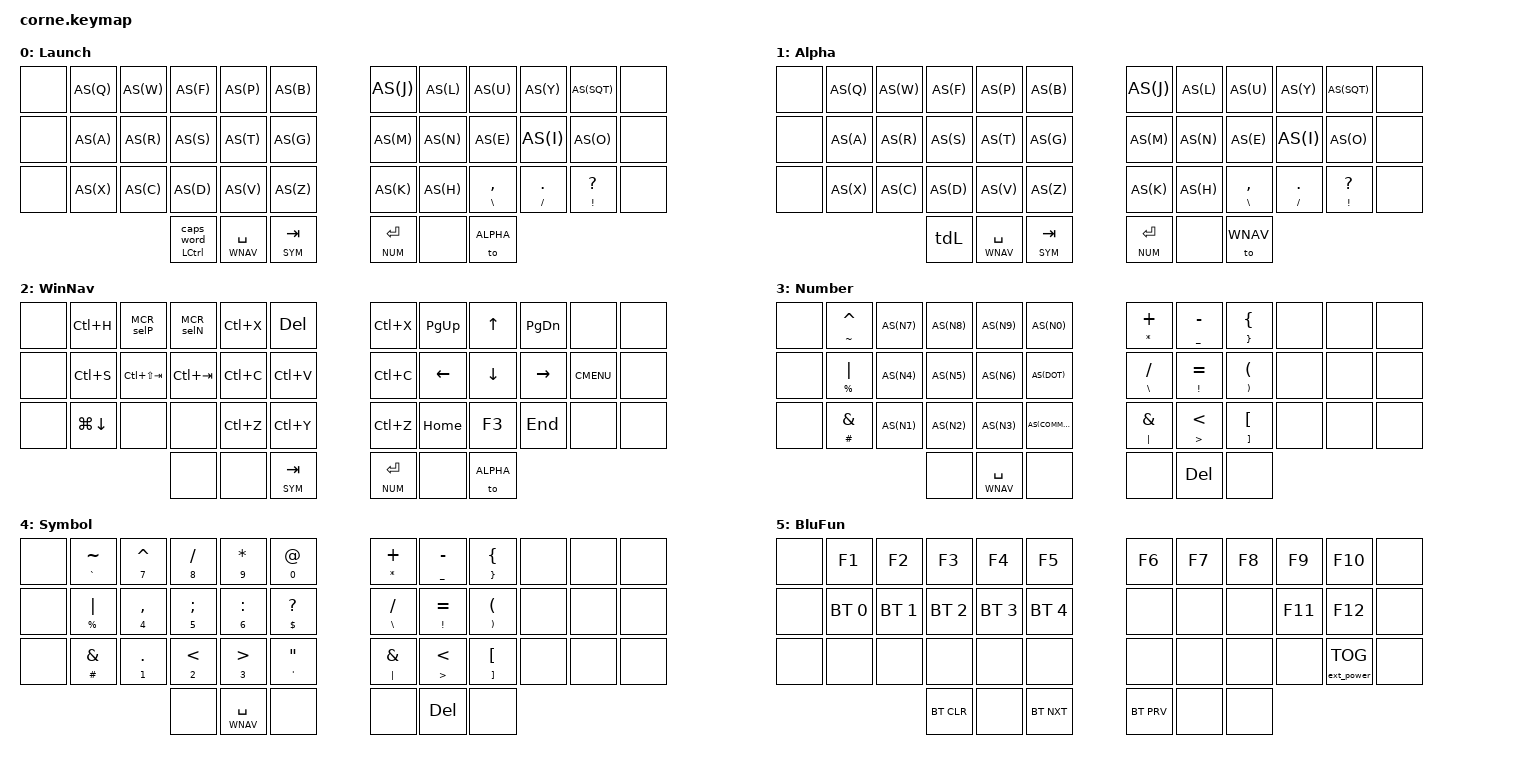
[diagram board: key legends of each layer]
/*
 * Copyright (c) 2020 The ZMK Contributors
 *
 * SPDX-License-Identifier: MIT
 */

#include <behaviors.dtsi>
#include <dt-bindings/zmk/keys.h>
#include <dt-bindings/zmk/bt.h>
#include <dt-bindings/zmk/ext_power.h>

#define XXX &none         // no physical keys
#define KNA &none         // key not applicable / unused

// Macros
#define AS(keycode) &as LS(keycode) keycode   // Autoshift
#define TS(keycode) &ts keycode keycode       // togglestick

// Windows Clipboard shortcuts
#define Win_RDO &kp LC(Y)
#define Win_PST &kp LC(V)
#define Win_CPY &kp LC(C)
#define Win_CUT &kp LC(X)
#define Win_UDO &kp LC(Z)
#define Win_REP &kp LC(H)
#define Win_SLA &kp LC(A)
#define Win_MIN &kp LG(DOWN)

// Layer definition
#define	LAUNCH  0
#define	ALPHA   1
#define	WNAV    2
#define	NUM     3
#define	SYM     4
#define	BLU     5
//#define VIM   6
//#define U_MEDIA  7
//#define U_NUM    8
//#define U_SYM    9
//#define U_FUN    10

/ {
    macros {
        MCR_selC: sel_word_cur {
            label = "macro_selectword_current";
            compatible = "zmk,behavior-macro";
            #binding-cells = <0>;
            bindings = <&macro_tap &kp LC(LEFT) &kp LC(LS(RIGHT))>;
        };
        MCR_selP: sel_word_prv {
            label = "macro_selectword_previous";
            compatible = "zmk,behavior-macro";
            #binding-cells = <0>;
            bindings = <&macro_tap &kp LC(LEFT) &kp LC(LEFT) &kp LC(LS(RIGHT))>;
        };
        MCR_selN: sel_word_nxt {
            label = "macro_selectword_next";
            compatible = "zmk,behavior-macro";
            #binding-cells = <0>;
            bindings = <&macro_tap &kp LC(RIGHT) &kp LC(LS(RIGHT))>;
        };
    };
};

/ {
    combos {
        compatible = "zmk,combos";
        combo_bspcL     { timeout-ms = <50>; key-positions = <15 16>; bindings = <&kp BSPC>;   };
        combo_bspcR     { timeout-ms = <50>; key-positions = <19 20>; bindings = <&kp BSPC>;   };
        combo_delL      { timeout-ms = <50>; key-positions = < 3  4>; bindings = <&kp DEL>;    };
        combo_delR      { timeout-ms = <50>; key-positions = < 7  8>; bindings = <&kp DEL>;    };
        combo_sysrstL   { timeout-ms = <50>; key-positions = < 1  5>; bindings = <&sys_reset>; };
        combo_sysrstR   { timeout-ms = <50>; key-positions = < 6 10>; bindings = <&sys_reset>; };
        combo_esc       { timeout-ms = <50>; key-positions = < 1  2>; bindings = <&kp ESC>;    };
        combo_blu_layer { timeout-ms = <50>; key-positions = < 1 25>; bindings = <&tog BLU>;   };
    };
};

/ {
     behaviors {
        as: auto_shift {
            compatible = "zmk,behavior-hold-tap";
            label = "AUTO_SHIFT";
            #binding-cells = <2>;
            tapping_term_ms = <150>;
            quick_tap_ms = <0>;
            flavor = "tap-preferred";
            bindings = <&kp>, <&kp>;
        }; 
        ts: toggle_stick {
            compatible = "zmk,behavior-hold-tap";
            label = "togglestick";
            #binding-cells = <2>;
            tapping_term_ms = <150>;
            flavor = "tap-preferred";
            bindings = <&sk>, <&kt>;
        };
        cc: caps_ctr {
          compatible = "zmk,behavior-hold-tap";
          label = "esc_cword";
          #binding-cells = <2>;
          tapping_term_ms = <200>;
          flavor = "hold-preferred";
          bindings = <&kp>, <&caps_word>;
        };
        tdL: tap_dance_mod_left {
            compatible = "zmk,behavior-tap-dance";
            label = "TD_MOD_LEFT";
            #binding-cells = <0>;
            tapping-term-ms = <200>;
            bindings = <&cc LCTRL 0>, <&mt LSHFT ESC>, <&mt LALT LG(L)>;
        };
     };

     keymap {
                compatible = "zmk,keymap";

                launch_layer {

                        label = "Launch";
                        bindings = <

XXX   AS(Q)             AS(W)             AS(F)             AS(P)             AS(B)             AS(J)             AS(L)             AS(U)             AS(Y)             AS(SQT)        XXX  
XXX   AS(A)             AS(R)             AS(S)             AS(T)             AS(G)             AS(M)             AS(N)             AS(E)             AS(I)             AS(O)          XXX  
XXX   AS(X)             AS(C)             AS(D)             AS(V)             AS(Z)             AS(K)             AS(H)             &mt BSLH COMMA    &mt FSLH DOT      &mt EXCL QMARK XXX  
                                          &cc LCTRL 0       &lt WNAV SPACE    &lt SYM TAB       &lt NUM RET       KNA               &to ALPHA
 
                        >;
                };

                alpha_layer {

                        label = "Alpha";
                        bindings = <

XXX   AS(Q)             AS(W)             AS(F)             AS(P)             AS(B)             AS(J)             AS(L)             AS(U)             AS(Y)             AS(SQT)        XXX  
XXX   AS(A)             AS(R)             AS(S)             AS(T)             AS(G)             AS(M)             AS(N)             AS(E)             AS(I)             AS(O)          XXX  
XXX   AS(X)             AS(C)             AS(D)             AS(V)             AS(Z)             AS(K)             AS(H)             &mt BSLH COMMA    &mt FSLH DOT      &mt EXCL QMARK XXX  
                                          &tdL              &lt WNAV SPACE    &lt SYM TAB       &lt NUM RET       KNA               &to WNAV
 
                        >;
                };

                win_nav_layer {

                        label = "WinNav";
                        bindings = <

XXX   Win_REP           &MCR_selP        &MCR_selN          Win_CUT           &kp DEL           Win_CUT           &kp PG_UP         &kp UP            &kp PG_DN         KNA              XXX  
XXX   &kp LC(S)         &kp LC(LS(TAB))  &kp LC(TAB)        Win_CPY           Win_PST           Win_CPY           &kp LEFT          &kp DOWN          &kp RIGHT         &kp K_CMENU      XXX  
XXX   Win_MIN           KNA              KNA                Win_UDO           Win_RDO           Win_UDO           &kp HOME          &kp F3            &kp END           KNA              XXX  
                                         KNA                KNA               &lt SYM TAB       &lt NUM RET       KNA               &to ALPHA

                        >;
                };

                num_layer {

                        label = "Number";
                        bindings = <

XXX   &mt TILDE CARET   AS(N7)           AS(N8)             AS(N9)            AS(N0)      /**/  &mt ASTRK PLUS    &mt UNDER MINUS   &mt RBRC LBRC     KNA               KNA              XXX  
XXX   &mt PRCNT PIPE    AS(N4)           AS(N5)             AS(N6)            AS(DOT)     /**/  &mt BSLH FSLH     &mt EXCL EQUAL    &mt RPAR LPAR     KNA               KNA              XXX  
XXX   &mt HASH AMPS     AS(N1)           AS(N2)             AS(N3)            AS(COMMA)   /**/  &mt PIPE AMPS     &mt GT LT         &mt RBKT LBKT     KNA               KNA              XXX  
                                         KNA                &lt WNAV SPACE    KNA         /**/  KNA               &kp DEL           KNA   
                        
                        >;
                };

                sym_layer {

                        label = "Symbol";
                        bindings = <

XXX   &mt GRAVE TILDE   &mt N7 CARET     &mt N8 FSLH        &mt N9 ASTRK      &mt N0 AT         &mt ASTRK PLUS    &mt UNDER MINUS   &mt RBRC LBRC     KNA               KNA            XXX  
XXX   &mt PRCNT PIPE    &mt N4 COMMA     &mt N5 SEMI        &mt N6 COLON      &mt DLLR QMARK    &mt BSLH FSLH     &mt EXCL EQUAL    &mt RPAR LPAR     KNA               KNA            XXX  
XXX   &mt HASH AMPS     &mt N1 DOT       &mt N2 LT          &mt N3 GT         &mt SQT DQT /**/  &mt PIPE AMPS     &mt GT LT         &mt RBKT LBKT     KNA               KNA            XXX  
                                         KNA                &lt WNAV SPACE    KNA         /**/  KNA               &kp DEL           KNA                           

                        >;
                };

                blu_layer {

                        label = "BluFun";
                        bindings = <
                        
XXX   &kp F1            &kp F2           &kp F3             &kp F4            &kp F5      /**/  &kp F6            &kp F7            &kp F8            &kp F9            &kp F10        XXX  
XXX   &bt BT_SEL 0      &bt BT_SEL 1     &bt BT_SEL 2       &bt BT_SEL 3      &bt BT_SEL 4      KNA               KNA               KNA               &kp F11           &kp F12        XXX  
XXX   KNA               KNA              KNA                KNA               KNA         /**/  KNA               KNA               KNA               KNA            &ext_power EP_TOG XXX  
                                         &bt BT_CLR         KNA               &bt BT_NXT  /**/  &bt BT_PRV        KNA               KNA   

                        >;
                };

        };
};
